# Cortex_M52 register map
Vendor: Arm Ltd.; Series: ARMv8.1-M Mainline; File version: 1.0.0
CPU: other r0p0, little endian, MPU, FPU, double-precision FPU, DSP, 8 interrupt priority bits
Registers are 32-bit, read-write, reset 0x0 unless marked. A register's access mark holds for its fields unless they carry their own. Offsets are from the block's base; [hi:lo] are bit positions; {n}, {i} and the like mark numbered series.

## DWT — Data Watchpoint and Trace unit: cycle counter and profiling counters, PC sampling, exception trace, and address/data comparators that raise watchpoints (halt or DebugMonitor), trigger the ETM/CTI or emit data trace. Needs DEMCR.TRCENA = 1.
Base 0xE0001000
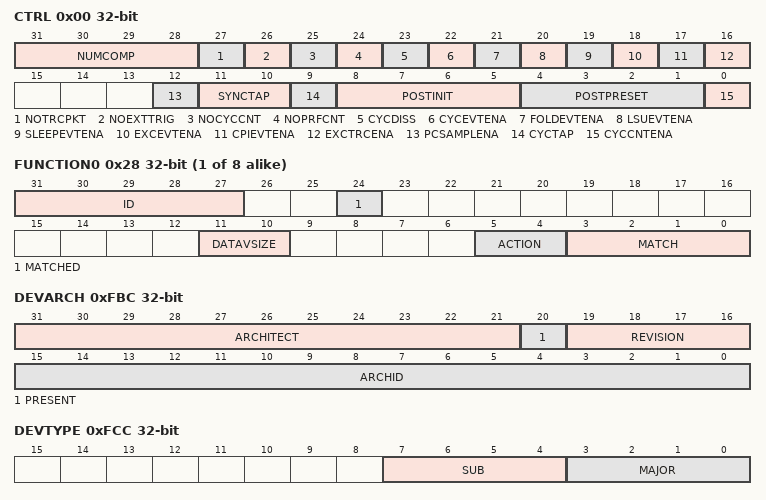
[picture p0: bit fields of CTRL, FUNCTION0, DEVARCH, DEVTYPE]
0x00 CTRL — DWT Control Register: cycle counter, PC sampling, exception trace and profiling event enables; read-only capability bits (NUMCOMP, NOCYCCNT...) in the top byte.
  [31:28] NUMCOMP ro — Number of comparators implemented (0-15; 4 on most Cortex-M3/M4/M7/M33 devices). Read-only.
  [27] NOTRCPKT ro — 1 = trace sampling and exception tracing (PC samples, data trace, exception trace) are not implemented. Read-only.
  [26] NOEXTTRIG ro — 1 = the CMPMATCH trigger outputs are not implemented. Read-only.
  [25] NOCYCCNT ro — 1 = CYCCNT is not implemented. Read-only.
  [24] NOPRFCNT ro — 1 = the profiling counters (CPICNT, EXCCNT, SLEEPCNT, LSUCNT, FOLDCNT) are not implemented. Read-only.
  [23] CYCDISS — Cycle counter disabled in Secure state (ARMv8-M): 1 = CYCCNT does not count while the processor is in Secure state. Secure access only.
  [22] CYCEVTENA — Enable the POSTCNT underflow (cycle count) event packet.
  [21] FOLDEVTENA — Enable the folded-instruction counter overflow event packet.
  [20] LSUEVTENA — Enable the LSU counter overflow event packet.
  [19] SLEEPEVTENA — Enable the sleep counter overflow event packet.
  [18] EXCEVTENA — Enable the exception overhead counter overflow event packet.
  [17] CPIEVTENA — Enable the CPI counter overflow event packet.
  [16] EXCTRCENA — Exception trace enable: emit packets on every exception entry, exit and return.
  [12] PCSAMPLENA — Periodic PC sample packets enable: a PC sample is emitted through the ITM every POSTCNT underflow (statistical profiling over SWO).
  [11:10] SYNCTAP — Synchronization packet interval (with TCR.SYNCENA): 0 = disabled, 1 = every 2^24 cycles (CYCCNT bit 24), 2 = 2^26, 3 = 2^28.
  [9] CYCTAP — CYCCNT tap that decrements POSTCNT: 0 = bit 6 (every 64 cycles), 1 = bit 10 (every 1024 cycles).
  [8:5] POSTINIT — Initial value of POSTCNT.
  [4:1] POSTPRESET — Reload value for the POSTCNT down-counter that divides the CYCTAP rate for PC sampling and CYCEVT events (0 = every tap).
  [0] CYCCNTENA — Cycle counter enable: 1 = CYCCNT counts (DEMCR.TRCENA must be 1). Reset value 0.
0x04 CYCCNT — Cycle Count Register: counts processor clock cycles while CTRL.CYCCNTENA = 1 (and DEMCR.TRCENA), wrapping at 2^32. Read for cycle-accurate timing; write to reset.
  [31:0] CYCCNT — Cycle count. Writable; write 0 to restart a measurement.
0x08 CPICNT — CPI Count Register: extra cycles (beyond the first) of every instruction, 8-bit, generating a CPI event on overflow when CTRL.CPIEVTENA is set.
  [7:0] CPICNT — Current CPI count (extra cycles per instruction), wraps at 256 with an event.
0x0C EXCCNT — Exception Overhead Count Register: cycles spent in exception entry and exit, 8-bit, event on overflow.
  [7:0] EXCCNT — Current exception overhead count, wraps at 256 with an event.
0x10 SLEEPCNT — Sleep Count Register: cycles spent sleeping, 8-bit, event on overflow.
  [7:0] SLEEPCNT — Current sleep cycle count, wraps at 256 with an event.
0x14 LSUCNT — LSU Count Register: extra cycles spent by load/store instructions, 8-bit, event on overflow.
  [7:0] LSUCNT — Current load/store extra-cycle count, wraps at 256 with an event.
0x18 FOLDCNT — Folded-instruction Count Register: instructions that took zero cycles (folded), 8-bit, event on overflow.
  [7:0] FOLDCNT — Current folded-instruction count, wraps at 256 with an event.
0x1C PCSR ro — Program Counter Sample Register: the address of a recently executed instruction - read repeatedly by a debugger for non-intrusive statistical profiling. 0xFFFFFFFF when halted.
  [31:0] EIASAMPLE — Sampled instruction address (0xFFFFFFFF when the processor is halted or PCSR is not implemented).
{0x20+0x10*i} COMP{i} (i=0..7) — Comparator Register {i}
  [31:0] COMP — Reference value for the comparator: an address, a data value (DATAVMATCH / MATCH = data value) or a cycle count.
{0x28+0x10*i} FUNCTION{i} (i=0..7) — Function Register {i}
  [31:27] ID ro — Read-only capability ID of this comparator: which MATCH types (cycle counter, instruction address, data address, data value, linked/limit) it supports - see the DWT_FUNCTION.ID table in the ARMv8-M ARM.
  [24] MATCHED — The comparator matched since this register was last read. Cleared on read.
  [11:10] DATAVSIZE — Size of the data value to match: 0 = byte, 1 = halfword, 2 = word.
  [5:4] ACTION — Action on match: 0 = trigger only (CMPMATCH to ETM/CTI), 1 = debug event (halt, or DebugMonitor), 2 = data trace packet (address/PC/value), 3 = both trace and trigger.
    0=Trigger (CMPMATCH trigger only); 1=DebugEvent (Watchpoint debug event); 2=Trace (Data trace packet); 3=TraceTrigger (Trace and trigger)
  [3:0] MATCH — ARMv8-M match type: 0 disabled, 1 cycle counter (comparator 0), 2 instruction address, 3 instruction address limit (with the previous comparator forms a range), 4 data address, 5 data address limit, 6 data address with data value (linked to the next comparator), 7 data address limit with value, 8 data value, 9 data address linked (for the value in the next comparator), 10 data address with value linked, 11-15 further data-value/range combinations. See the ARMv8-M ARM DWT_FUNCTION table and ID for what this comparator supports.
0x3C VMASK1 — Comparator Value Mask 1
0x5C VMASK3 — Comparator Value Mask 3
0xFBC DEVARCH ro — Device Architecture Register: CoreSight ARCHID of the DWT (0x1A02).
  [31:21] ARCHITECT — JEP106 code of the architect (Arm: 0x23B).
  [20] PRESENT — 1 = DEVARCH is present and its contents are valid.
  [19:16] REVISION — Architecture revision.
  [15:0] ARCHID — Architecture ID, including the architecture part number [11:0] and revision [15:12].
0xFCC DEVTYPE ro — Device Type Register: 0x00 (miscellaneous).
  [7:4] SUB — Sub type within the major class.
  [3:0] MAJOR — Major type: 0 miscellaneous, 1 trace sink, 2 trace link, 3 trace source, 4 debug control, 5 debug logic, 6 PMU.
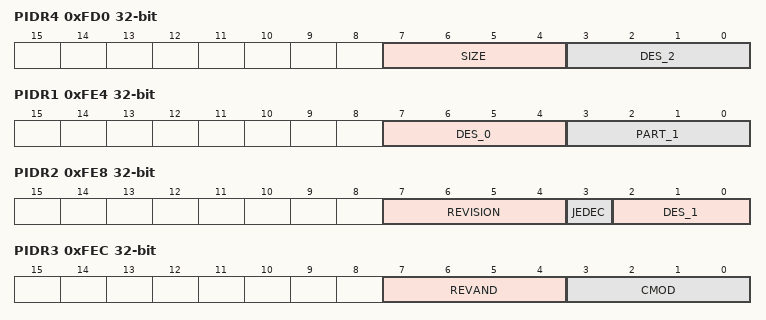
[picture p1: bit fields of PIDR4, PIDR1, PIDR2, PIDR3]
0xFD0 PIDR4 ro — Peripheral Identification Register 4: JEP106 continuation code and component size.
  [7:4] SIZE — Log2 of the number of 4 KB blocks the component occupies (0 = one block).
  [3:0] DES_2 — JEP106 continuation code of the designer (Arm: 0x4).
{0xFC0+4i} PIDR{i} ro (i=5..7) — Peripheral Identification Register {i} (reserved, reads as zero).
0xFE0 PIDR0 ro — Peripheral Identification Register 0: part number bits [7:0].
  [7:0] PART_0 — Part number bits [7:0].
0xFE4 PIDR1 ro — Peripheral Identification Register 1: part number bits [11:8] and designer bits [3:0].
  [7:4] DES_0 — JEP106 identity code bits [3:0] of the designer.
  [3:0] PART_1 — Part number bits [11:8].
0xFE8 PIDR2 ro — Peripheral Identification Register 2: designer bits [6:4], JEDEC flag and revision.
  [7:4] REVISION — Component major revision.
  [3] JEDEC — Always 1: the designer ID is a JEDEC JEP106 code.
  [2:0] DES_1 — JEP106 identity code bits [6:4] of the designer.
0xFEC PIDR3 ro — Peripheral Identification Register 3: customer modified and minor revision.
  [7:4] REVAND — Minor revision (metal fix) number.
  [3:0] CMOD — Customer Modified: 0 if the component has not been modified by the integrator.
0xFF0 CIDR0 ro — Component Identification Register 0: preamble byte 0 (0x0D).
  [7:0] PRMBL_0 — Preamble, reads as 0x0D.
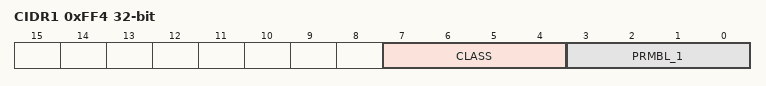
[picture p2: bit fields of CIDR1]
0xFF4 CIDR1 ro — Component Identification Register 1: component class and preamble.
  [7:4] CLASS — Component class: 0x1 ROM table, 0x9 CoreSight component, 0xE generic IP, 0xF CoreLink/PrimeCell.
  [3:0] PRMBL_1 — Preamble, reads as 0x0.
0xFF8 CIDR2 ro — Component Identification Register 2: preamble byte 2 (0x05).
  [7:0] PRMBL_2 — Preamble, reads as 0x05.
0xFFC CIDR3 ro — Component Identification Register 3: preamble byte 3 (0xB1).
  [7:0] PRMBL_3 — Preamble, reads as 0xB1.
